# CH32X315 register map
Vendor: WCH Ltd.; File version: 1.1
Registers are 32-bit, read-write, reset 0x0 unless marked. A register's access mark holds for its fields unless they carry their own. Offsets are from the block's base; [hi:lo] are bit positions; {n}, {i} and the like mark numbered series.

## USBHS — USB register
Base 0x40030000
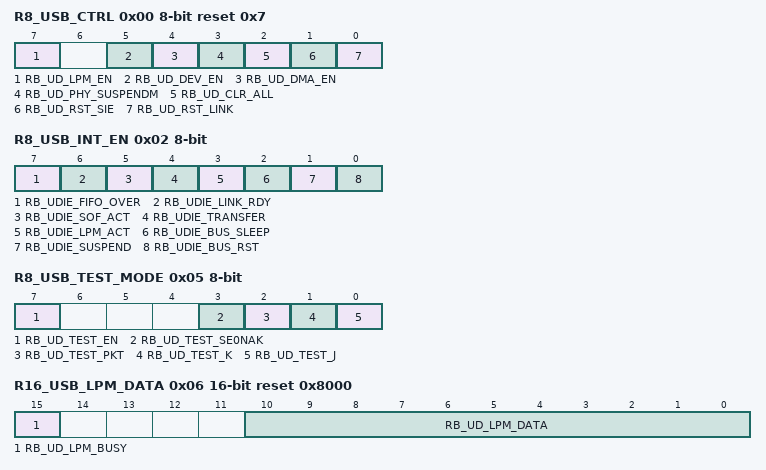
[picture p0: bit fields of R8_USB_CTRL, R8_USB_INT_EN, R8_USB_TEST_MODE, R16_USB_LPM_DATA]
0x00 R8_USB_CTRL 8-bit reset 0x7 — USB base control register
  [7] RB_UD_LPM_EN — LPM enable
  [5] RB_UD_DEV_EN — USB device enabled
  [4] RB_UD_DMA_EN — DMA transfer enabled
  [3] RB_UD_PHY_SUSPENDM — USB PHY suspend
  [2] RB_UD_CLR_ALL — clear all interrupt flags
  [1] RB_UD_RST_SIE — USB protocol processor reset
  [0] RB_UD_RST_LINK — LINK layer reset,highly effective
0x01 R8_USB_BASE_MODE 8-bit — USB mode control register
  [1:0] RB_UD_SPEED_TYPE — The desired speed mode of the device
0x02 R8_USB_INT_EN 8-bit — USB interrupt enable register
  [7] RB_UDIE_FIFO_OVER — USB Overflow interrupt enable
  [6] RB_UDIE_LINK_RDY — USB connection interrupt enable
  [5] RB_UDIE_SOF_ACT — Receive SOF packet interrupt enable
  [4] RB_UDIE_TRANSFER — USB transfer end interrupt enabled
  [3] RB_UDIE_LPM_ACT — LMP transfer end interrupt enabled
  [2] RB_UDIE_BUS_SLEEP — USB bus sleep interrupt enabled
  [1] RB_UDIE_SUSPEND — USB bus pause interrupt enabled
  [0] RB_UDIE_BUS_RST — USB bus reset interrupt enabled
0x03 R8_USB_DEV_AD 8-bit — USB device address
  [6:0] RB_MASK_USB_ADDR — bit mask for USB device address
0x04 R8_USB_WAKE_CTRL 16-bit — USB remote wake up register
  [0] RB_UD_REMOTE_WKUP — remote wake up
0x05 R8_USB_TEST_MODE 8-bit — USB test mode register
  [7] RB_UD_TEST_EN — test mode enable
  [3] RB_UD_TEST_SE0NAK — test mode,output SEO
  [2] RB_UD_TEST_PKT — test mode,output a packet
  [1] RB_UD_TEST_K — test mode,output K
  [0] RB_UD_TEST_J — test mode,output J
0x06 R16_USB_LPM_DATA 16-bit access per field reset 0x8000 — USB power management register
  [15] RB_UD_LPM_BUSY rw — power management busy
  [10:0] RB_UD_LPM_DATA ro — power management data
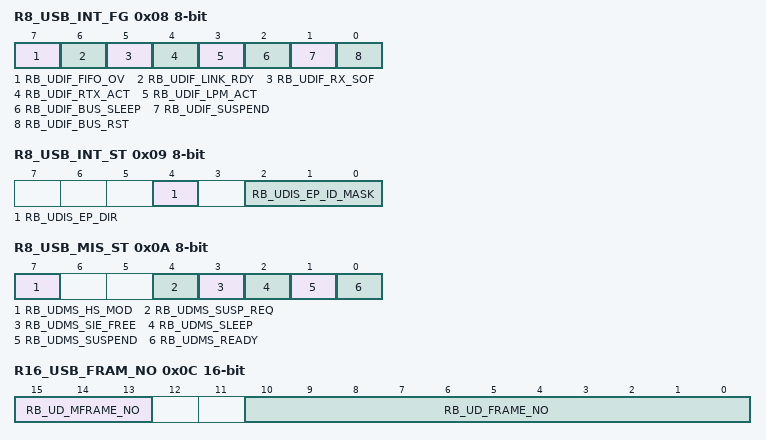
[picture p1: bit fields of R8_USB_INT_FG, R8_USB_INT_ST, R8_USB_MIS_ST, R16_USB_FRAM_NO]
0x08 R8_USB_INT_FG 8-bit access per field — USB interrupt flag register
  [7] RB_UDIF_FIFO_OV rw — USB Overflow interrupt flag
  [6] RB_UDIF_LINK_RDY rw — USB connection interrupt flag
  [5] RB_UDIF_RX_SOF rw — Receive SOF packet interrupt flag
  [4] RB_UDIF_RTX_ACT ro — USB transmission end interrupt flag
  [3] RB_UDIF_LPM_ACT rw — LPM transmission end interrupt flag
  [2] RB_UDIF_BUS_SLEEP rw — USB bus sleep interrupt flag
  [1] RB_UDIF_SUSPEND rw — USB bus suspend interrupt flag
  [0] RB_UDIF_BUS_RST rw — USB bus reset interrupt flag
0x09 R8_USB_INT_ST 8-bit ro — USB interrupt status
  [4] RB_UDIS_EP_DIR — Endpoint data transmission direction
  [2:0] RB_UDIS_EP_ID_MASK — The endpoint number at which the data transfer occurs
0x0A R8_USB_MIS_ST 8-bit ro — USB miscellaneous status
  [7] RB_UDMS_HS_MOD — whether the host is high-speed
  [4] RB_UDMS_SUSP_REQ — USB suspends the request
  [3] RB_UDMS_SIE_FREE — USB free status
  [2] RB_UDMS_SLEEP — USB sleep status
  [1] RB_UDMS_SUSPEND — USB suspend status
  [0] RB_UDMS_READY — USB connection status
0x0C R16_USB_FRAM_NO 16-bit ro — USB frame number
  [15:13] RB_UD_MFRAME_NO — Received micro frame number
  [10:0] RB_UD_FRAME_NO — Received frame number
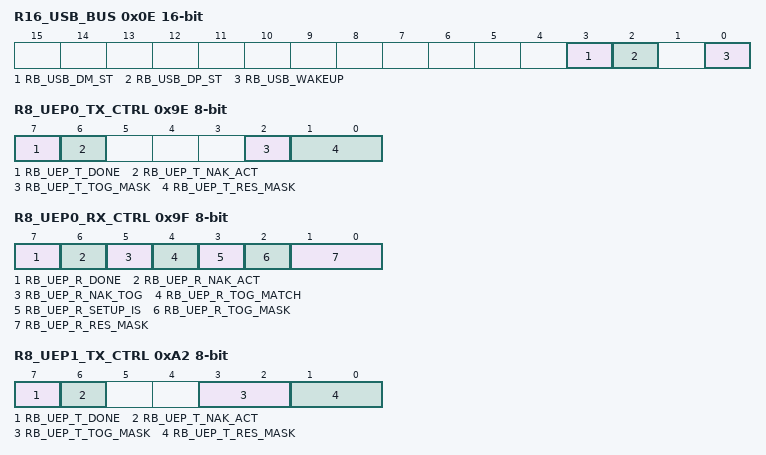
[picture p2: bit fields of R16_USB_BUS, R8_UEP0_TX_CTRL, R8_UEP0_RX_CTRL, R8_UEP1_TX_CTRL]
0x0E R16_USB_BUS 16-bit ro — USB bus
  [3] RB_USB_DM_ST — UDM status
  [2] RB_USB_DP_ST — UDP status
  [0] RB_USB_WAKEUP — USB wakeup
0x10 UEP_TX_EN 16-bit — USB endpoint sends the enable register
  [15:0] RB_UEP_TX_EN — Endpoint 0 to 15 sends enable
0x12 UEP_RX_EN 16-bit — USB endpoint receive the enable registers
  [15:0] RB_UEP_RX_EN — Endpoint 0 to 15 receive enable
0x14 R16_UEP_T_TOG_AUTO 16-bit — USB endpoint sends the auto-filp enable register
  [7:0] RB_UEP_T_TOG_AUTO — 0 to 7 endpoint synchronization triggers bit auto-filp enable
0x16 R16_UEP_R_TOG_AUTO 16-bit — USB endpoint receive the auto-filp enable register
  [7:0] RB_UEP_R_TOG_AUTO — 0 to 7 endpoint synchronization triggers bit auto-filp enable
0x18 R8_UEP_T_BURST 8-bit — USB endpoint sends a burst register
  [7:0] RB_UEP_T_BURST_EN — 0 to 7 endpoint send burst enable
0x19 R16_UEP_T_BURST_MODE 8-bit — USB endpoint send the mode register
  [7:0] RB_UEP_T_BURST_MODE — 0 to 7 endpoint send the mode enable
0x1A R8_UEP_R_BURST 8-bit — USB endpoint receives the burst register
  [7:0] RB_UEP_R_BURST_EN — 0 to 7 endpoint receive burst enable
0x1B R8_UEP_R_RES_MODE 8-bit — USB endpoint reply mode register
  [7:0] RB_UEP_R_RES_MODE — 0 to 7 endpoint reply mode
0x1C R32_UEP_AF_MODE — USB endpoint muitiplexing register
  [7:1] RB_UEP_T_AF — 1 to 7 endpoint muitiplexing enables
0x20 R32_UEP0_DMA — The start address register of the endpoint 0 buffer
  [23:0] UEP0_DMA — The start address of the endpoint 0 buffer
{0x20+4i} R32_UEP{i}_RX_DMA (i=1..7) — endpoint {i} receives the start address register of the buffer
  [23:0] UEP{i}_RX_DMA — endpoint receives the start address register of the buffer
{0x3C+4i} R32_UEP{i}_TX_DMA (i=1..7) — endpoint {i} sends the start address register of the buffer
  [23:0] UEP{i}_TX_DMA — endpoint sends the start address register of the buffer
0x5C R32_UEP0_MAX_LEN — endpoint 0 max length packet register
  [6:0] UEP0_MAX_LEN — endpoint 0 max acceptable offset length
{0x5C+4i} R32_UEP{i}_MAX_LEN (i=1..7) — endpoint {i} max length packet register
  [10:0] UEP{i}_MAX_LEN — endpoint {i} max acceptable offset length
0x7C R16_UEP0_RX_LEN 16-bit — endpoint 0 acceptable length
  [6:0] UEP0_RX_LEN — endpoint 0 acceptable data length
{0x7C+4i} R16_UEP{i}_RX_LEN 16-bit (i=1..5) — endpoint {i} receives the lenth register in a single pass
  [15:0] UEP{i}_RX_LEN — the length of data received by endpoint {i} in a single pass
{0x7E+4i} R16_UEP{i}_R_SIZE 16-bit (i=1..7) — the length register of the total received data at endpoint {i}
  [15:0] UEP{i}_R_SIZE — the length of the total received data at endpoint {i}
0x94 UEP6_RX_LEN 16-bit — endpoint 6 receives the lenth register in a single pass
  [15:0] UEP6_RX_LEN — the length of data received by endpoint 6 in a single pass
0x98 R16_UEP7_RX_LEN 16-bit — endpoint 7 receives the lenth register in a single pass
  [15:0] UEP7_RX_LEN — the length of data received by endpoint 7 in a single pass
0x9C R16_UEP0_T_LEN 16-bit — endpoint 0 send the length
  [6:0] UEP0_T_LEN
0x9E R8_UEP0_TX_CTRL 8-bit — endpoint 0 send control register
  [7] RB_UEP_T_DONE — endpoint 0 sends the end of NAK flag
  [6] RB_UEP_T_NAK_ACT — endpoint 0 sends the end flag
  [2] RB_UEP_T_TOG_MASK — endpoint 0 synchronous trigger bit for the sender to prepare
  [1:0] RB_UEP_T_RES_MASK — endpoint 0 control of the send response to IN transactions
0x9F R8_UEP0_RX_CTRL 8-bit access per field — endpoint 0 send control register
  [7] RB_UEP_R_DONE rw — endpoint 0 receives the end flag
  [6] RB_UEP_R_NAK_ACT rw — endpoint 0 receives the end of NAK flag
  [5] RB_UEP_R_NAK_TOG ro — endpoint 0 for the received return NAK,packet type
  [4] RB_UEP_R_TOG_MATCH ro — received synchronization trigger bit matches the desired synchronization trigger bit state
  [3] RB_UEP_R_SETUP_IS ro — whether endpoint 0 receives a SETUP transaction
  [2] RB_UEP_R_TOG_MASK rw — the reception of endpoint 0 expects a synchronous trigger bit
  [1:0] RB_UEP_R_RES_MASK rw — endpoint 0 has control over the received response
{0x9C+4i} R16_UEP{i}_T_LEN 16-bit (i=1..7) — endpoint {i} send the length register
  [15:0] UEP{i}_T_LEN — endpoint {i} send the length
0xA2 R8_UEP1_TX_CTRL 8-bit — endpoint 1 send control register
  [7] RB_UEP_T_DONE — endpoint 1 sends the end of NAK flag
  [6] RB_UEP_T_NAK_ACT — endpoint 1 sends the end flag
  [3:2] RB_UEP_T_TOG_MASK — endpoint 1 synchronous trigger bit for the sender to prepare
  [1:0] RB_UEP_T_RES_MASK — endpoint 1 control of the send response to IN transactions
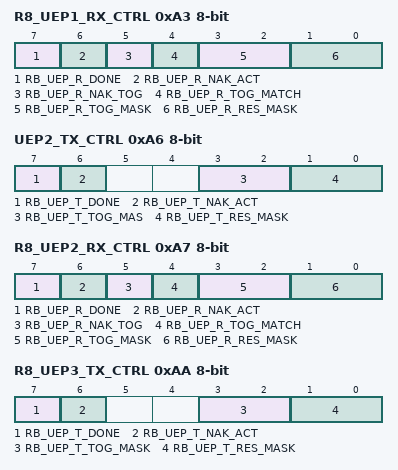
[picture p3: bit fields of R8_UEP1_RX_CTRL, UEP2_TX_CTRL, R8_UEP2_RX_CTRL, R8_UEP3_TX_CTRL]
0xA3 R8_UEP1_RX_CTRL 8-bit access per field — endpoint 1 receive control
  [7] RB_UEP_R_DONE rw — endpoint 1 receives the end flag
  [6] RB_UEP_R_NAK_ACT rw — endpoint 1 receives the end of NAK flag
  [5] RB_UEP_R_NAK_TOG ro — endpoint 1 for the received return NAK,packet type
  [4] RB_UEP_R_TOG_MATCH ro — received synchronization trigger bit matches the desired synchronization trigger bit state
  [3:2] RB_UEP_R_TOG_MASK rw — the reception of endpoint 1 expects a synchronous trigger bit
  [1:0] RB_UEP_R_RES_MASK rw — endpoint 1 has control over the received response
0xA6 UEP2_TX_CTRL 8-bit — endpoint 2 send control register
  [7] RB_UEP_T_DONE — endpoint 2 sends the end of NAK flag
  [6] RB_UEP_T_NAK_ACT — endpoint 2 sends the end flag
  [3:2] RB_UEP_T_TOG_MAS — endpoint 2 synchronous trigger bit for the sender to prepare
  [1:0] RB_UEP_T_RES_MASK — endpoint 2 control of the send response to IN transactions
0xA7 R8_UEP2_RX_CTRL 8-bit access per field — endpoint 2 receive control
  [7] RB_UEP_R_DONE rw — endpoint 2 receives the end flag
  [6] RB_UEP_R_NAK_ACT rw — endpoint 2 receives the end of NAK flag
  [5] RB_UEP_R_NAK_TOG ro — endpoint 2 for the received return NAK,packet type
  [4] RB_UEP_R_TOG_MATCH ro — received synchronization trigger bit matches the desired synchronization trigger bit state
  [3:2] RB_UEP_R_TOG_MASK rw — the reception of endpoint 2 expects a synchronous trigger bit
  [1:0] RB_UEP_R_RES_MASK rw — endpoint 2 has control over the received response
0xAA R8_UEP3_TX_CTRL 8-bit — endpoint 3 send control register
  [7] RB_UEP_T_DONE — endpoint 3 sends the end of NAK flag
  [6] RB_UEP_T_NAK_ACT — endpoint 3 sends the end flag
  [3:2] RB_UEP_T_TOG_MASK — endpoint 3 synchronous trigger bit for the sender to prepare
  [1:0] RB_UEP_T_RES_MASK — endpoint 3 control of the send response to IN transactions
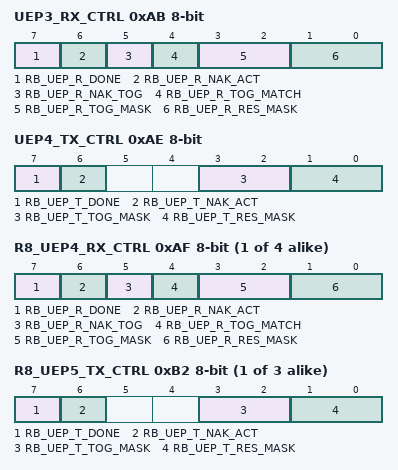
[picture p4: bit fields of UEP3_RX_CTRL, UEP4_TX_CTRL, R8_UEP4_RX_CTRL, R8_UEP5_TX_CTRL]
0xAB UEP3_RX_CTRL 8-bit access per field — endpoint 3 receive control
  [7] RB_UEP_R_DONE rw — endpoint 3 receives the end flag
  [6] RB_UEP_R_NAK_ACT rw — endpoint 3 receives the end of NAK flag
  [5] RB_UEP_R_NAK_TOG ro — endpoint 3 for the received return NAK,packet type
  [4] RB_UEP_R_TOG_MATCH ro — received synchronization trigger bit matches the desired synchronization trigger bit state
  [3:2] RB_UEP_R_TOG_MASK rw — the reception of endpoint 3 expects a synchronous trigger bit
  [1:0] RB_UEP_R_RES_MASK rw — endpoint 3 has control over the received response
0xAE UEP4_TX_CTRL 8-bit — endpoint 4 send control register
  [7] RB_UEP_T_DONE — endpoint 4 sends the end of NAK flag
  [6] RB_UEP_T_NAK_ACT — endpoint 4 sends the end flag
  [3:2] RB_UEP_T_TOG_MASK — endpoint 4 synchronous trigger bit for the sender to prepare
  [1:0] RB_UEP_T_RES_MASK — endpoint 4 control of the send response to IN transactions
{0x9F+4i} R8_UEP{i}_RX_CTRL 8-bit access per field (i=4..7) — endpoint {i} receive control
  [7] RB_UEP_R_DONE rw — endpoint {i} receives the end flag
  [6] RB_UEP_R_NAK_ACT rw — endpoint {i} receives the end of NAK flag
  [5] RB_UEP_R_NAK_TOG ro — endpoint {i} for the received return NAK,packet type
  [4] RB_UEP_R_TOG_MATCH ro — received synchronization trigger bit matches the desired synchronization trigger bit state
  [3:2] RB_UEP_R_TOG_MASK rw — the reception of endpoint {i} expects a synchronous trigger bit
  [1:0] RB_UEP_R_RES_MASK rw — endpoint {i} has control over the received response
{0x9E+4i} R8_UEP{i}_TX_CTRL 8-bit (i=5..7) — endpoint {i} send control register
  [7] RB_UEP_T_DONE — endpoint {i} sends the end of NAK flag
  [6] RB_UEP_T_NAK_ACT — endpoint {i} sends the end flag
  [3:2] RB_UEP_T_TOG_MASK — endpoint {i} synchronous trigger bit for the sender to prepare
  [1:0] RB_UEP_T_RES_MASK — endpoint {i} control of the send response to IN transactions
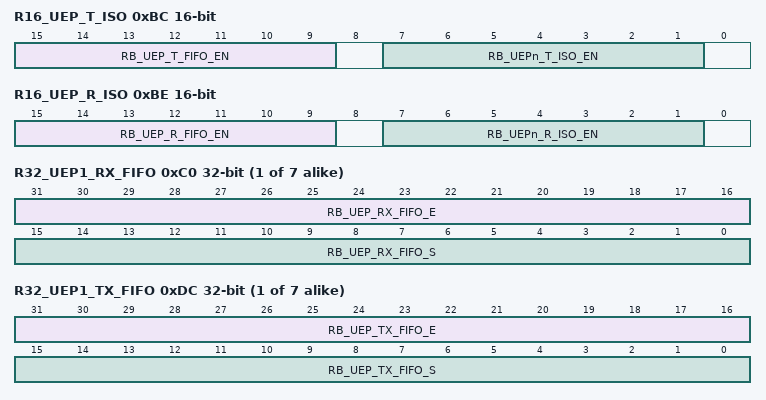
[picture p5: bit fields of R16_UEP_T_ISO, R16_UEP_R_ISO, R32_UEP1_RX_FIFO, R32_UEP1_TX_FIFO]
0xBC R16_UEP_T_ISO 16-bit — usb endpoint sends a synchronous mode enable register
  [15:9] RB_UEP_T_FIFO_EN — The FIFO mode of the TX of the endpoint is enabled
  [7:1] RB_UEPn_T_ISO_EN — upload endpoint(IN) synchronization mode enabled
0xBE R16_UEP_R_ISO 16-bit — usb endpoint receives a synchronous mode enable register
  [15:9] RB_UEP_R_FIFO_EN — The FIFO mode of the TX of the endpoint is enabled
  [7:1] RB_UEPn_R_ISO_EN — down endpoint(OUT) synchronization mode enabled
{0xBC+4i} R32_UEP{i}_RX_FIFO (i=1..7) — Receive FIFO address of usb endpoint {i}
  [31:16] RB_UEP_RX_FIFO_E — The end FIFO address of the receiving endpoint
  [15:0] RB_UEP_RX_FIFO_S — The FIFO start address of the receiving endpoint
{0xD8+4i} R32_UEP{i}_TX_FIFO (i=1..7) — The sending FIFO address of usb endpoint {i}
  [31:16] RB_UEP_TX_FIFO_E — The end FIFO address of the sending endpoint
  [15:0] RB_UEP_TX_FIFO_S — The FIFO start address of the sending endpoint
0xF8 R32_16K_MODE_CTRL — USBHS 16K mode control register
  [7:1] RB_UEP_16KMODE_EN — the USBHS endpoint 16K mode
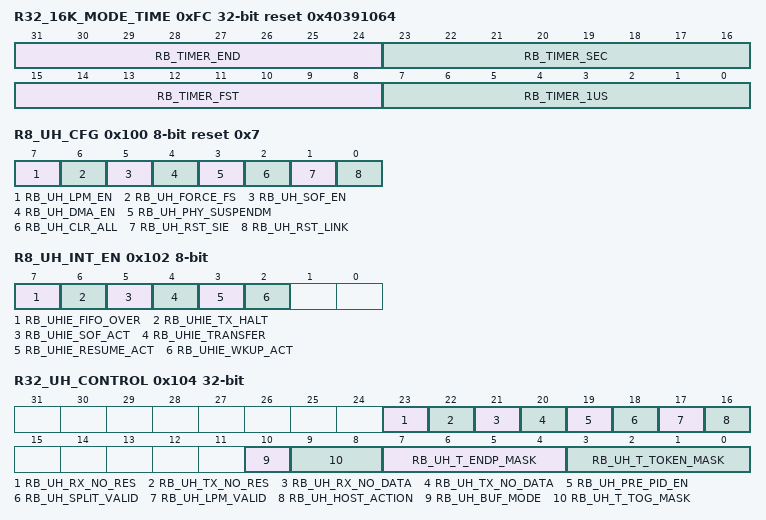
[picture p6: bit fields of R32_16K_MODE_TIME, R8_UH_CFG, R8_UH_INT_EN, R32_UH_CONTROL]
0xFC R32_16K_MODE_TIME reset 0x40391064 — USBHS 16K mode time control register
  [31:24] RB_TIMER_END — Stop the time window for delivery
  [23:16] RB_TIMER_SEC — The second time window for delivery
  [15:8] RB_TIMER_FST — The first time window for delivery
  [7:0] RB_TIMER_1US — 1 microsecond sa the basic timing unit
0x100 R8_UH_CFG 8-bit reset 0x7 — USB host Configuration register
  [7] RB_UH_LPM_EN — LPM enable
  [6] RB_UH_FORCE_FS — forced full speed FS
  [5] RB_UH_SOF_EN — sof packet sending function enabled
  [4] RB_UH_DMA_EN — DMA transfer enabled
  [3] RB_UH_PHY_SUSPENDM — PHY suspend,close utmi clock
  [2] RB_UH_CLR_ALL — clear all interrupt flags
  [1] RB_UH_RST_SIE — USB protocol processor reset
  [0] RB_UH_RST_LINK — USB connection controller module resets
0x102 R8_UH_INT_EN 8-bit — USB host interrupt enable register
  [7] RB_UHIE_FIFO_OVER — FIFO overflow interrupt enable
  [6] RB_UHIE_TX_HALT — send pause interrupt enable
  [5] RB_UHIE_SOF_ACT — sof packet sending interruption is enabled
  [4] RB_UHIE_TRANSFER — USB transfer end interrupt enabled
  [3] RB_UHIE_RESUME_ACT — bus recovery interrupt was enabled
  [2] RB_UHIE_WKUP_ACT — Wakeup interrupt enabled
0x103 R8_UH_DEV_AD 8-bit — USB host device address register
  [6:0] RB_UH_DEV_ADDR — device address
0x104 R32_UH_CONTROL — USB host control register
  [23] RB_UH_RX_NO_RES — IN-DATA no answer,used for synchronous transfer or high-speed SPLIT packets
  [22] RB_UH_TX_NO_RES — OUT or SETUP DATA no reply is extended and is used for synchronous transmission or hign-speed SPLIT packets
  [21] RB_UH_RX_NO_DATA — DATA packets are not expected after IN token packets and are used for high-speed SPLIT packets
  [20] RB_UH_TX_NO_DATA — OUT or SETUP token packet packets are followed by no data packets for hign-speed SPLIT packets
  [19] RB_UH_PRE_PID_EN — this bit is enabled when the port is operating at full speed and needs to send low speed packets(PRE)
  [18] RB_UH_SPLIT_VALID — valid to send SPLIT packet
  [17] RB_UH_LPM_VALID — valid to send LMP packet
  [16] RB_UH_HOST_ACTION — host enables the transaction
  [10] RB_UH_BUF_MODE — DATA cache control bit
  [9:8] RB_UH_T_TOG_MASK — send data PID
  [7:4] RB_UH_T_ENDP_MASK — transaction token packet endpoint number
  [3:0] RB_UH_T_TOKEN_MASK — transaction token packet PID
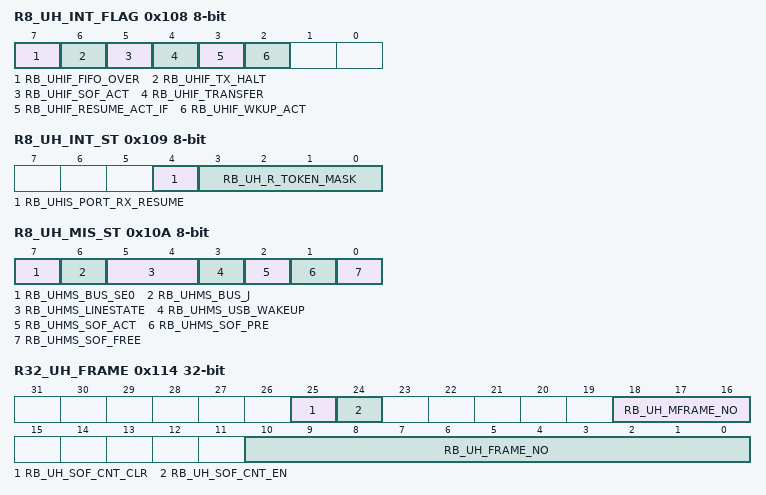
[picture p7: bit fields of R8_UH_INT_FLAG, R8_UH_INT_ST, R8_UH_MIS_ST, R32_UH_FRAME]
0x108 R8_UH_INT_FLAG 8-bit — USB HOST interrupt flag register
  [7] RB_UHIF_FIFO_OVER — FIFO overflow interrupt flag
  [6] RB_UHIF_TX_HALT — send pause interrupt flag
  [5] RB_UHIF_SOF_ACT — sof packet delivert completion interrupt flag
  [4] RB_UHIF_TRANSFER — USB transaction transfer completion interrupt flag
  [3] RB_UHIF_RESUME_ACT_IF — bus recovery interrupt flag
  [2] RB_UHIF_WKUP_ACT — Wakeup interrupt flag
0x109 R8_UH_INT_ST 8-bit access per field — USB host interrupt status
  [4] RB_UHIS_PORT_RX_RESUME rw — A bit of indicates that the port received a wakeup signal
  [3:0] RB_UH_R_TOKEN_MASK ro — received PID
0x10A R8_UH_MIS_ST 8-bit access per field — USB host miscellaneous status
  [7] RB_UHMS_BUS_SE0 ro — SE0 on USB bus
  [6] RB_UHMS_BUS_J rw — J on USB bus
  [5:4] RB_UHMS_LINESTATE ro — USB bus status
  [3] RB_UHMS_USB_WAKEUP rw — USB bus wakes up
  [2] RB_UHMS_SOF_ACT rw — USB bus SOF status
  [1] RB_UHMS_SOF_PRE ro — The state of the USB SOF packet is indicated as follows
  [0] RB_UHMS_SOF_FREE ro — port enabled state
0x10C R32_UH_LPM_DATA — USB host power management data register
  [10:0] RB_UH_LPM_DATA — power management data
0x110 R32_UH_SPLIT_DATA — USB host SPLIT register
  [18:0] RB_UH_SPLIT_DATA — SPLIT management data
0x114 R32_UH_FRAME access per field — USB host frame register
  [25] RB_UH_SOF_CNT_CLR rw — the SOF count is cleared
  [24] RB_UH_SOF_CNT_EN rw — SOF count enabled
  [18:16] RB_UH_MFRAME_NO ro — microfame number
  [10:0] RB_UH_FRAME_NO rw — the frame number
0x118 R32_UH_TX_LEN — USB host send length register
  [10:0] RB_UH_TX_LEN — send data length
0x11C R32_UH_RX_LEN — USB host receive length register
  [10:0] RB_UH_RX_LEN — Received data length
0x120 R32_UH_RX_MAX_LEN — USB host receives the maximum length register
  [10:0] RB_UH_RX_MAX_LEN — receives the maximum length
0x124 R32_UH_RX_DMA — DMA receive address register
  [23:0] R32_UH_RX_DMA — Received address
0x128 R32_UH_TX_DMA — DMA send address register
  [23:0] R32_UH_TX_DMA — Send address
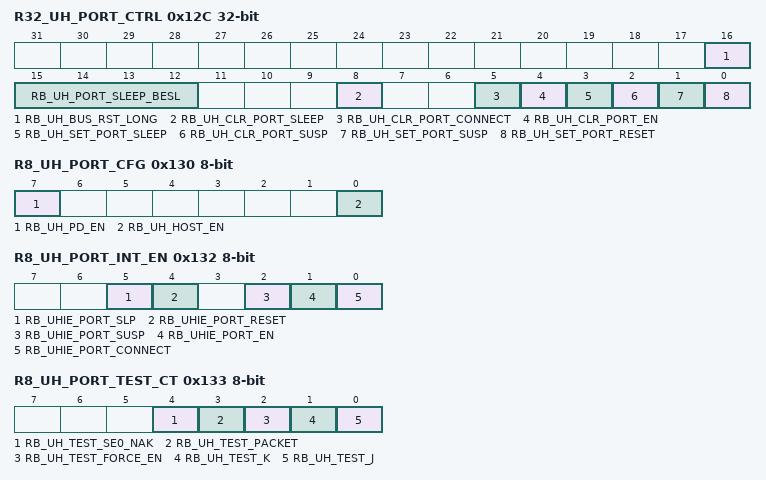
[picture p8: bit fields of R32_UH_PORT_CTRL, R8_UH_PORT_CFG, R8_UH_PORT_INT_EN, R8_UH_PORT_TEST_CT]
0x12C R32_UH_PORT_CTRL access per field — USB host port control register
  [16] RB_UH_BUS_RST_LONG rw — BUS reset time selection
  [15:12] RB_UH_PORT_SLEEP_BESL rw — wake-up time control
  [8] RB_UH_CLR_PORT_SLEEP wo — the PORT exits the sleep state (LPM)
  [5] RB_UH_CLR_PORT_CONNECT wo — bring the PORT into the port state
  [4] RB_UH_CLR_PORT_EN wo — PORT exits the enabled state and enters the DISABLED state
  [3] RB_UH_SET_PORT_SLEEP wo — the PORT goes to sleep(LPM)
  [2] RB_UH_CLR_PORT_SUSP wo — the PORT exits the suspended state
  [1] RB_UH_SET_PORT_SUSP wo — the PORT is in a suspended state
  [0] RB_UH_SET_PORT_RESET wo — PORT send reset
0x130 R8_UH_PORT_CFG 8-bit — USB host port Configuration register
  [7] RB_UH_PD_EN — the 15k resistance drop-down function is enable in host mode
  [0] RB_UH_HOST_EN — USB port mode selection
0x132 R8_UH_PORT_INT_EN 8-bit — USB host port interrupt enable register
  [5] RB_UHIE_PORT_SLP — port sleep state change interrupt enabled
  [4] RB_UHIE_PORT_RESET — port reset state change interrupt enabled
  [2] RB_UHIE_PORT_SUSP — port pause state change interrupt enabled
  [1] RB_UHIE_PORT_EN — port enable state change interrupt enabled
  [0] RB_UHIE_PORT_CONNECT — port connection state change interrupt enabled
0x133 R8_UH_PORT_TEST_CT 8-bit — USB host port test mode register
  [4] RB_UH_TEST_SE0_NAK — test SE0 NAK
  [3] RB_UH_TEST_PACKET — test packet
  [2] RB_UH_TEST_FORCE_EN — test mode was enabled
  [1] RB_UH_TEST_K — test output K
  [0] RB_UH_TEST_J — test output J
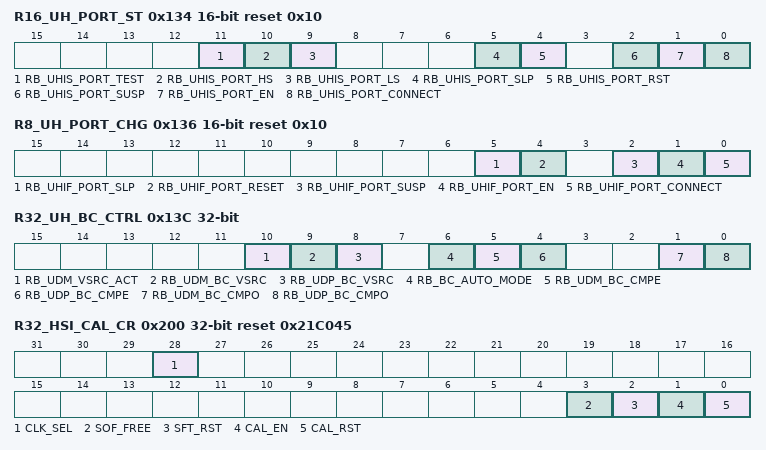
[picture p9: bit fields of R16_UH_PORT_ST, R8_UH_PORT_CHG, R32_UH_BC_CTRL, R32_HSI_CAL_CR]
0x134 R16_UH_PORT_ST 16-bit ro reset 0x10 — USB host port status register
  [11] RB_UHIS_PORT_TEST — whether the port is in test mode
  [10] RB_UHIS_PORT_HS — whether the port connection speed is hign
  [9] RB_UHIS_PORT_LS — whether the port connection speed is low
  [5] RB_UHIS_PORT_SLP — port sleep
  [4] RB_UHIS_PORT_RST — port reset status
  [2] RB_UHIS_PORT_SUSP — port pause state
  [1] RB_UHIS_PORT_EN — port enabled
  [0] RB_UHIS_PORT_C0NNECT — port connection state
0x136 R8_UH_PORT_CHG 16-bit ro reset 0x10 — USB host port state charge register
  [5] RB_UHIF_PORT_SLP — port sleep state charge
  [4] RB_UHIF_PORT_RESET — port reset state charge
  [2] RB_UHIF_PORT_SUSP — port pause state charge
  [1] RB_UHIF_PORT_EN — port enable state charge
  [0] RB_UHIF_PORT_CONNECT — port connection state charge
0x13C R32_UH_BC_CTRL access per field — USB host BC charging control register
  [10] RB_UDM_VSRC_ACT ro — In automatic mode, UDP outputs VBC_SRC ,otherwise it is controlled by UDM_BC_CMPE
  [9] RB_UDM_BC_VSRC rw — UDM pin BC protocol source voltage enabled
  [8] RB_UDP_BC_VSRC rw — UDP pin BC protocol source voltage enabled
  [6] RB_BC_AUTO_MODE rw — Automatic mode enables
  [5] RB_UDM_BC_CMPE rw — UDM pin BC protocol comparator enables
  [4] RB_UDP_BC_CMPE rw — UDP pin BC protocol comparator enables
  [1] RB_UDM_BC_CMPO ro — UDM pin BC protocol comparator status
  [0] RB_UDP_BC_CMPO ro — UDP pin BC protocol comparator status
0x200 R32_HSI_CAL_CR reset 0x21C045 — HSI calibration control register
  [28] CLK_SEL — selection clock
  [3] SOF_FREE — the uplink interface enters the enable mode
  [2] SFT_RST — exit fine calibration mode
  [1] CAL_EN — calibration enable
  [0] CAL_RST — global reset of the calibration module
